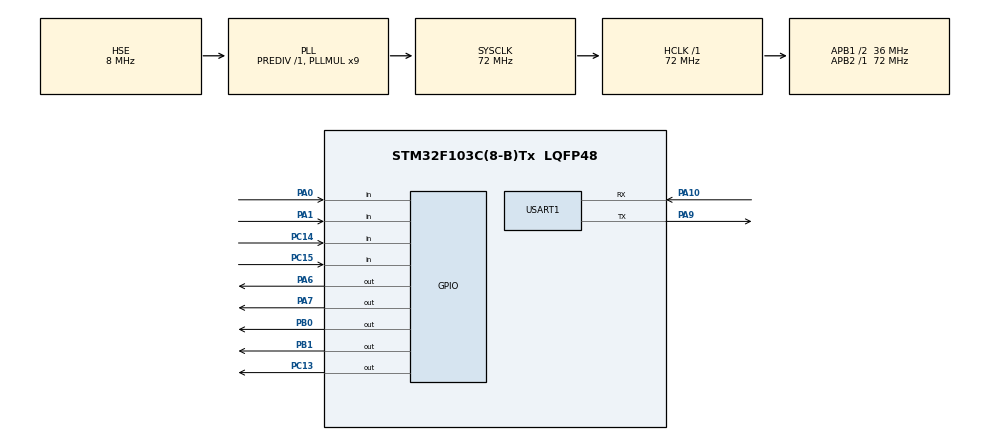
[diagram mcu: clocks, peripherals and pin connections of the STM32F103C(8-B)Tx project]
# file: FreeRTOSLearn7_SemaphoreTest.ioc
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FREERTOS.BinarySemaphores01=myBinarySem01,Dynamic,NULL,Available
FREERTOS.CountingSemaphores01=myCountingSem01,4,Dynamic,NULL,0
FREERTOS.INCLUDE_xTaskGetHandle=1
FREERTOS.Mutexes01=myMutex01,Dynamic,NULL,Available
FREERTOS.Queues01=ButtonQueue,1,uint8_t,0,Dynamic,NULL,NULL;TimerQueue,1,uint16_t,0,Dynamic,NULL,NULL;PrintQueue,10,uint8_t *,0,Dynamic,NULL,NULL
FREERTOS.Tasks01=defaultTask,8,128,StartDefaultTask,Default,NULL,Dynamic,NULL,NULL;HighTask,40,128,vHighTask,Default,NULL,Dynamic,NULL,NULL;MidTask,24,128,vMidTask,Default,NULL,Dynamic,NULL,NULL;LowtTask1,8,128,vLowTask1,Default,NULL,Dynamic,NULL,NULL
FREERTOS.configTOTAL_HEAP_SIZE=4096
Mcu.Family=STM32F1
Mcu.Name=STM32F103C(8-B)Tx
Mcu.Package=LQFP48
NVIC.PriorityGroup=NVIC_PRIORITYGROUP_4
NVIC.TIM1_UP_IRQn=true\:5\:0\:false\:false\:true\:true\:true\:true\:true
PA0-WKUP.GPIO_PuPd=GPIO_PULLUP
PA0-WKUP.Signal=GPIO_Input
PA1.GPIO_PuPd=GPIO_PULLUP
PA1.Signal=GPIO_Input
PA10.Mode=Asynchronous
PA10.Signal=USART1_RX
PA13.Mode=Serial_Wire
PA13.Signal=SYS_JTMS-SWDIO
PA14.Mode=Serial_Wire
PA14.Signal=SYS_JTCK-SWCLK
PA6.PinState=GPIO_PIN_SET
PA6.Signal=GPIO_Output
PA7.PinState=GPIO_PIN_SET
PA7.Signal=GPIO_Output
PA9.Mode=Asynchronous
PA9.Signal=USART1_TX
PB0.PinState=GPIO_PIN_SET
PB0.Signal=GPIO_Output
PB1.PinState=GPIO_PIN_SET
PB1.Signal=GPIO_Output
PC13-TAMPER-RTC.Signal=GPIO_Output
PC14-OSC32_IN.GPIO_PuPd=GPIO_PULLUP
PC14-OSC32_IN.Signal=GPIO_Input
PC15-OSC32_OUT.GPIO_PuPd=GPIO_PULLUP
PC15-OSC32_OUT.Signal=GPIO_Input
PD0-OSC_IN.Mode=HSE-External-Oscillator
PD0-OSC_IN.Signal=RCC_OSC_IN
PD1-OSC_OUT.Mode=HSE-External-Oscillator
PD1-OSC_OUT.Signal=RCC_OSC_OUT
ProjectManager.HeapSize=0x200
ProjectManager.StackSize=0x400
ProjectManager.TargetToolchain=MDK-ARM V5.32
RCC.AHBFreq_Value=72000000
RCC.APB1CLKDivider=RCC_HCLK_DIV2
RCC.APB1Freq_Value=36000000
RCC.APB1TimFreq_Value=72000000
RCC.APB2Freq_Value=72000000
RCC.APB2TimFreq_Value=72000000
RCC.HCLKFreq_Value=72000000
RCC.PLLMUL=RCC_PLL_MUL9
RCC.PLLSourceVirtual=RCC_PLLSOURCE_HSE
RCC.SYSCLKFreq_VALUE=72000000
RCC.SYSCLKSource=RCC_SYSCLKSOURCE_PLLCLK
RCC.USBFreq_Value=72000000
TIM1.Period=7200-1
TIM1.Prescaler=9
USART1.VirtualMode=VM_ASYNC
VP_FREERTOS_VS_CMSIS_V2.Mode=CMSIS_V2
VP_TIM1_VS_ClockSourceINT.Mode=Internal
board=custom

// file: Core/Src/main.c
/* USER CODE BEGIN Header */
/**
  ******************************************************************************
  * @file           : main.c
  * @brief          : Main program body
  ******************************************************************************
  * @attention
  *
  * Copyright (c) 2026 STMicroelectronics.
  * All rights reserved.
  *
  * This software is licensed under terms that can be found in the LICENSE file
  * in the root directory of this software component.
  * If no LICENSE file comes with this software, it is provided AS-IS.
  *
  ******************************************************************************
  */
/* USER CODE END Header */
#include "main.h"
#include "cmsis_os.h"

/* USER CODE BEGIN Includes */
#include "UserTask.h"
/* USER CODE END Includes */

TIM_HandleTypeDef htim1;

UART_HandleTypeDef huart1;

/* Definitions for defaultTask */
osThreadId_t defaultTaskHandle;
const osThreadAttr_t defaultTask_attributes = {
  .name = "defaultTask",
  .stack_size = 128 * 4,
  .priority = (osPriority_t) osPriorityLow,
};
/* Definitions for HighTask */
osThreadId_t HighTaskHandle;
const osThreadAttr_t HighTask_attributes = {
  .name = "HighTask",
  .stack_size = 128 * 4,
  .priority = (osPriority_t) osPriorityHigh,
};
/* Definitions for MidTask */
osThreadId_t MidTaskHandle;
const osThreadAttr_t MidTask_attributes = {
  .name = "MidTask",
  .stack_size = 128 * 4,
  .priority = (osPriority_t) osPriorityNormal,
};
/* Definitions for LowtTask1 */
osThreadId_t LowtTask1Handle;
const osThreadAttr_t LowtTask1_attributes = {
  .name = "LowtTask1",
  .stack_size = 128 * 4,
  .priority = (osPriority_t) osPriorityLow,
};
/* Definitions for ButtonQueue */
osMessageQueueId_t ButtonQueueHandle;
const osMessageQueueAttr_t ButtonQueue_attributes = {
  .name = "ButtonQueue"
};
/* Definitions for TimerQueue */
osMessageQueueId_t TimerQueueHandle;
const osMessageQueueAttr_t TimerQueue_attributes = {
  .name = "TimerQueue"
};
/* Definitions for PrintQueue */
osMessageQueueId_t PrintQueueHandle;
const osMessageQueueAttr_t PrintQueue_attributes = {
  .name = "PrintQueue"
};
/* Definitions for myMutex01 */
osMutexId_t myMutex01Handle;
const osMutexAttr_t myMutex01_attributes = {
  .name = "myMutex01"
};
/* Definitions for myBinarySem01 */
osSemaphoreId_t myBinarySem01Handle;
const osSemaphoreAttr_t myBinarySem01_attributes = {
  .name = "myBinarySem01"
};
/* Definitions for myCountingSem01 */
osSemaphoreId_t myCountingSem01Handle;
const osSemaphoreAttr_t myCountingSem01_attributes = {
  .name = "myCountingSem01"
};

void SystemClock_Config(void);
static void MX_GPIO_Init(void);
static void MX_USART1_UART_Init(void);
static void MX_TIM1_Init(void);
void StartDefaultTask(void *argument);
void vHighTask(void *argument);
void vMidTask(void *argument);
void vLowTask1(void *argument);

int main(void)
{

  /* MCU Configuration--------------------------------------------------------*/

  /* Reset of all peripherals, Initializes the Flash interface and the Systick. */
  HAL_Init();

  /* Configure the system clock */
  SystemClock_Config();

  /* Initialize all configured peripherals */
  MX_GPIO_Init();
  MX_USART1_UART_Init();
  MX_TIM1_Init();

  /* Init scheduler */
  osKernelInitialize();
  /* Create the mutex(es) */
  /* creation of myMutex01 */
  myMutex01Handle = osMutexNew(&myMutex01_attributes);

  /* Create the semaphores(s) */
  /* creation of myBinarySem01 */
  myBinarySem01Handle = osSemaphoreNew(1, 1, &myBinarySem01_attributes);

  /* creation of myCountingSem01 */
  myCountingSem01Handle = osSemaphoreNew(4, 0, &myCountingSem01_attributes);

  /* Create the queue(s) */
  /* creation of ButtonQueue */
  ButtonQueueHandle = osMessageQueueNew (1, sizeof(uint8_t), &ButtonQueue_attributes);

  /* creation of TimerQueue */
  TimerQueueHandle = osMessageQueueNew (1, sizeof(uint16_t), &TimerQueue_attributes);

  /* creation of PrintQueue */
  PrintQueueHandle = osMessageQueueNew (10, sizeof(uint8_t *), &PrintQueue_attributes);

  /* Create the thread(s) */
  /* creation of defaultTask */
  defaultTaskHandle = osThreadNew(StartDefaultTask, NULL, &defaultTask_attributes);

  /* creation of HighTask */
  HighTaskHandle = osThreadNew(vHighTask, NULL, &HighTask_attributes);

  /* creation of MidTask */
  MidTaskHandle = osThreadNew(vMidTask, NULL, &MidTask_attributes);

  /* creation of LowtTask1 */
  LowtTask1Handle = osThreadNew(vLowTask1, NULL, &LowtTask1_attributes);

  /* Start scheduler */
  osKernelStart();

  /* We should never get here as control is now taken by the scheduler */

  /* Infinite loop */
  while (1)
  {

  }
}

void SystemClock_Config(void)
{
  RCC_OscInitTypeDef RCC_OscInitStruct = {0};
  RCC_ClkInitTypeDef RCC_ClkInitStruct = {0};

  /** Initializes the RCC Oscillators according to the specified parameters
  * in the RCC_OscInitTypeDef structure.
  */
  RCC_OscInitStruct.OscillatorType = RCC_OSCILLATORTYPE_HSE;
  RCC_OscInitStruct.HSEState = RCC_HSE_ON;
  RCC_OscInitStruct.HSEPredivValue = RCC_HSE_PREDIV_DIV1;
  RCC_OscInitStruct.HSIState = RCC_HSI_ON;
  RCC_OscInitStruct.PLL.PLLState = RCC_PLL_ON;
  RCC_OscInitStruct.PLL.PLLSource = RCC_PLLSOURCE_HSE;
  RCC_OscInitStruct.PLL.PLLMUL = RCC_PLL_MUL9;
  if (HAL_RCC_OscConfig(&RCC_OscInitStruct) != HAL_OK)
  {
    Error_Handler();
  }

  /** Initializes the CPU, AHB and APB buses clocks
  */
  RCC_ClkInitStruct.ClockType = RCC_CLOCKTYPE_HCLK|RCC_CLOCKTYPE_SYSCLK
                              |RCC_CLOCKTYPE_PCLK1|RCC_CLOCKTYPE_PCLK2;
  RCC_ClkInitStruct.SYSCLKSource = RCC_SYSCLKSOURCE_PLLCLK;
  RCC_ClkInitStruct.AHBCLKDivider = RCC_SYSCLK_DIV1;
  RCC_ClkInitStruct.APB1CLKDivider = RCC_HCLK_DIV2;
  RCC_ClkInitStruct.APB2CLKDivider = RCC_HCLK_DIV1;

  if (HAL_RCC_ClockConfig(&RCC_ClkInitStruct, FLASH_LATENCY_2) != HAL_OK)
  {
    Error_Handler();
  }
}

static void MX_TIM1_Init(void)
{

  TIM_ClockConfigTypeDef sClockSourceConfig = {0};
  TIM_MasterConfigTypeDef sMasterConfig = {0};

  htim1.Instance = TIM1;
  htim1.Init.Prescaler = 9;
  htim1.Init.CounterMode = TIM_COUNTERMODE_UP;
  htim1.Init.Period = 7200-1;
  htim1.Init.ClockDivision = TIM_CLOCKDIVISION_DIV1;
  htim1.Init.RepetitionCounter = 0;
  htim1.Init.AutoReloadPreload = TIM_AUTORELOAD_PRELOAD_DISABLE;
  if (HAL_TIM_Base_Init(&htim1) != HAL_OK)
  {
    Error_Handler();
  }
  sClockSourceConfig.ClockSource = TIM_CLOCKSOURCE_INTERNAL;
  if (HAL_TIM_ConfigClockSource(&htim1, &sClockSourceConfig) != HAL_OK)
  {
    Error_Handler();
  }
  sMasterConfig.MasterOutputTrigger = TIM_TRGO_RESET;
  sMasterConfig.MasterSlaveMode = TIM_MASTERSLAVEMODE_DISABLE;
  if (HAL_TIMEx_MasterConfigSynchronization(&htim1, &sMasterConfig) != HAL_OK)
  {
    Error_Handler();
  }
  /* USER CODE BEGIN TIM1_Init 2 */
	__HAL_TIM_ENABLE_IT(&htim1,TIM_IT_UPDATE);//开启中断
HAL_TIM_Base_Start(&htim1);//配置定时器
  /* USER CODE END TIM1_Init 2 */

}

static void MX_USART1_UART_Init(void)
{

  huart1.Instance = USART1;
  huart1.Init.BaudRate = 115200;
  huart1.Init.WordLength = UART_WORDLENGTH_8B;
  huart1.Init.StopBits = UART_STOPBITS_1;
  huart1.Init.Parity = UART_PARITY_NONE;
  huart1.Init.Mode = UART_MODE_TX_RX;
  huart1.Init.HwFlowCtl = UART_HWCONTROL_NONE;
  huart1.Init.OverSampling = UART_OVERSAMPLING_16;
  if (HAL_UART_Init(&huart1) != HAL_OK)
  {
    Error_Handler();
  }

}

static void MX_GPIO_Init(void)
{
  GPIO_InitTypeDef GPIO_InitStruct = {0};

  /* GPIO Ports Clock Enable */
  __HAL_RCC_GPIOC_CLK_ENABLE();
  __HAL_RCC_GPIOD_CLK_ENABLE();
  __HAL_RCC_GPIOA_CLK_ENABLE();
  __HAL_RCC_GPIOB_CLK_ENABLE();

  /*Configure GPIO pin Output Level */
  HAL_GPIO_WritePin(GPIOC, GPIO_PIN_13, GPIO_PIN_RESET);

  /*Configure GPIO pin Output Level */
  HAL_GPIO_WritePin(GPIOA, GPIO_PIN_6|GPIO_PIN_7, GPIO_PIN_SET);

  /*Configure GPIO pin Output Level */
  HAL_GPIO_WritePin(GPIOB, GPIO_PIN_0|GPIO_PIN_1, GPIO_PIN_SET);

  /*Configure GPIO pin : PC13 */
  GPIO_InitStruct.Pin = GPIO_PIN_13;
  GPIO_InitStruct.Mode = GPIO_MODE_OUTPUT_PP;
  GPIO_InitStruct.Pull = GPIO_NOPULL;
  GPIO_InitStruct.Speed = GPIO_SPEED_FREQ_LOW;
  HAL_GPIO_Init(GPIOC, &GPIO_InitStruct);

  /*Configure GPIO pins : PC14 PC15 */
  GPIO_InitStruct.Pin = GPIO_PIN_14|GPIO_PIN_15;
  GPIO_InitStruct.Mode = GPIO_MODE_INPUT;
  GPIO_InitStruct.Pull = GPIO_PULLUP;
  HAL_GPIO_Init(GPIOC, &GPIO_InitStruct);

  /*Configure GPIO pins : PA0 PA1 */
  GPIO_InitStruct.Pin = GPIO_PIN_0|GPIO_PIN_1;
  GPIO_InitStruct.Mode = GPIO_MODE_INPUT;
  GPIO_InitStruct.Pull = GPIO_PULLUP;
  HAL_GPIO_Init(GPIOA, &GPIO_InitStruct);

  /*Configure GPIO pins : PA6 PA7 */
  GPIO_InitStruct.Pin = GPIO_PIN_6|GPIO_PIN_7;
  GPIO_InitStruct.Mode = GPIO_MODE_OUTPUT_PP;
  GPIO_InitStruct.Pull = GPIO_NOPULL;
  GPIO_InitStruct.Speed = GPIO_SPEED_FREQ_LOW;
  HAL_GPIO_Init(GPIOA, &GPIO_InitStruct);

  /*Configure GPIO pins : PB0 PB1 */
  GPIO_InitStruct.Pin = GPIO_PIN_0|GPIO_PIN_1;
  GPIO_InitStruct.Mode = GPIO_MODE_OUTPUT_PP;
  GPIO_InitStruct.Pull = GPIO_NOPULL;
  GPIO_InitStruct.Speed = GPIO_SPEED_FREQ_LOW;
  HAL_GPIO_Init(GPIOB, &GPIO_InitStruct);

}

void StartDefaultTask(void *argument)
{
  for(;;)
  {
  }
}

void vHighTask(void *argument)
{
  /* USER CODE BEGIN vHighTask */
  /* Infinite loop */
  for(;;)
  {
    HighExecute();
  }
  /* USER CODE END vHighTask */
}

void vMidTask(void *argument)
{
  /* USER CODE BEGIN vMidTask */
  /* Infinite loop */
  for(;;)
  {
    MidExecute();
  }
  /* USER CODE END vMidTask */
}

void vLowTask1(void *argument)
{
  /* USER CODE BEGIN vLowTask1 */
  /* Infinite loop */
  for(;;)
  {
    LowExecute();
  }
  /* USER CODE END vLowTask1 */
}

void Error_Handler(void)
{
  __disable_irq();
  while (1)
  {
  }
}
